# MKL02Z4 register map
Vendor: Freescale Semiconductor, Inc.; File version: 1.6
CPU: CM0PLUS r0p0, little endian, no MPU, no FPU, 0x2 interrupt priority bits, 0x0 interrupts
Registers are 32-bit, read-write, reset 0x0 unless marked. A register's access mark holds for its fields unless they carry their own. Offsets are from the block's base; [hi:lo] are bit positions.

## OSC0 — Oscillator
Base 0x40065000; register names take the prefix OSC0_
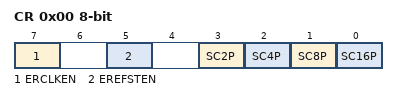
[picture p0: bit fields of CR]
0x00 CR 8-bit — OSC Control Register
  [7] ERCLKEN — External Reference Enable
    0=External reference clock is inactive; 1=External reference clock is enabled
  [5] EREFSTEN — External Reference Stop Enable
    0=External reference clock is disabled in Stop mode; 1=External reference clock stays enabled in Stop mode if ERCLKEN is set before entering Stop mode
  [3] SC2P — Oscillator 2 pF Capacitor Load Configure
    0=Disable the selection; 1=Add 2 pF capacitor to the oscillator load
  [2] SC4P — Oscillator 4 pF Capacitor Load Configure
    0=Disable the selection; 1=Add 4 pF capacitor to the oscillator load
  [1] SC8P — Oscillator 8 pF Capacitor Load Configure
    0=Disable the selection; 1=Add 8 pF capacitor to the oscillator load
  [0] SC16P — Oscillator 16 pF Capacitor Load Configure
    0=Disable the selection; 1=Add 16 pF capacitor to the oscillator load

## I2C0 — Inter-Integrated Circuit
Base 0x40066000; register names take the prefix I2C0_
0x00 A1 8-bit — I2C Address Register 1
  [7:1] AD — Address
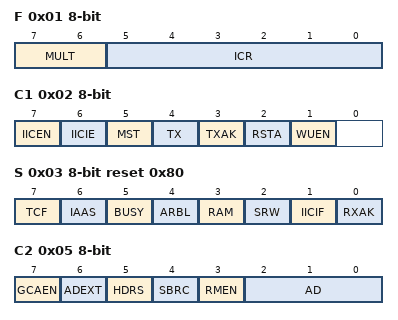
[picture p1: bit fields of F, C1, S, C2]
0x01 F 8-bit — I2C Frequency Divider register
  [7:6] MULT — The MULT bits define the multiplier factor mul
    0=mul = 1; 1=mul = 2; 2=mul = 4
  [5:0] ICR — ClockRate
0x02 C1 8-bit — I2C Control Register 1
  [7] IICEN — I2C Enable
    0=Disabled; 1=Enabled
  [6] IICIE — I2C Interrupt Enable
    0=Disabled; 1=Enabled
  [5] MST — Master Mode Select
    0=Slave mode; 1=Master mode
  [4] TX — Transmit Mode Select
    0=Receive; 1=Transmit
  [3] TXAK — Transmit Acknowledge Enable
    0=An acknowledge signal is sent to the bus on the following receiving byte; 1=No acknowledge signal is sent to the bus on the following receiving data byte
  [2] RSTA wo — Repeat START
  [1] WUEN — Wakeup Enable
    0=Normal operation. No interrupt generated when address matching in low power mode.; 1=Enables the wakeup function in low power mode
0x03 S 8-bit reset 0x80 — I2C Status register
  [7] TCF ro — Transfer Complete Flag
    0=Transfer in progress; 1=Transfer complete
  [6] IAAS — Addressed As A Slave
    0=Not addressed; 1=Addressed as a slave
  [5] BUSY ro — Bus Busy
    0=Bus is idle; 1=Bus is busy
  [4] ARBL — Arbitration Lost
    0=Standard bus operation; 1=Loss of arbitration
  [3] RAM — Range Address Match
    0=Not addressed; 1=Addressed as a slave
  [2] SRW ro — Slave Read/Write
    0=Slave receive, master writing to slave; 1=Slave transmit, master reading from slave
  [1] IICIF — Interrupt Flag
    0=No interrupt pending; 1=Interrupt pending
  [0] RXAK ro — Receive Acknowledge
    0=Acknowledge signal was received after the completion of one byte of data transmission on the bus; 1=No acknowledge signal detected
0x04 D 8-bit — I2C Data I/O register
  [7:0] DATA
0x05 C2 8-bit — I2C Control Register 2
  [7] GCAEN — General Call Address Enable
    0=Disabled; 1=Enabled
  [6] ADEXT — Address Extension
    0=7-bit address scheme; 1=10-bit address scheme
  [5] HDRS — High Drive Select
    0=Normal drive mode; 1=High drive mode
  [4] SBRC — Slave Baud Rate Control
    0=The slave baud rate follows the master baud rate and clock stretching may occur; 1=Slave baud rate is independent of the master baud rate
  [3] RMEN — Range Address Matching Enable
    0=Range mode disabled. No address match occurs for an address within the range of values of the A1 and RA registers.; 1=Range mode enabled. Address matching occurs when a slave receives an address within the range of values of the A1 and RA registers.
  [2:0] AD — Slave Address
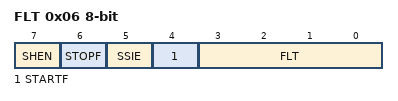
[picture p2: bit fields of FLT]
0x06 FLT 8-bit — I2C Programmable Input Glitch Filter register
  [7] SHEN — Stop Hold Enable
    0=Stop holdoff is disabled. The MCU's entry to stop mode is not gated.; 1=Stop holdoff is enabled
  [6] STOPF — I2C Bus Stop Detect Flag
    0=No stop happens on I2C bus; 1=Stop detected on I2C bus
  [5] SSIE — I2C Bus Stop or Start Interrupt Enable
    0=Stop or start detection interrupt is disabled; 1=Stop or start detection interrupt is enabled
  [4] STARTF — I2C Bus Start Detect Flag
    0=No start happens on I2C bus; 1=Start detected on I2C bus
  [3:0] FLT — I2C Programmable Filter Factor
    0=No filter/bypass
0x07 RA 8-bit — I2C Range Address register
  [7:1] RAD — Range Slave Address

## I2C1 — Inter-Integrated Circuit
Base 0x40067000; register names take the prefix I2C1_
Registers as I2C0.
